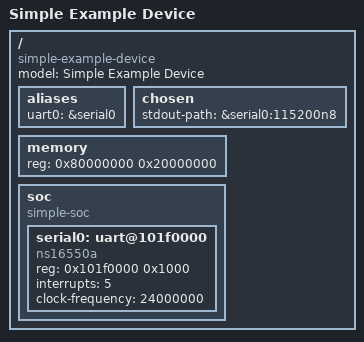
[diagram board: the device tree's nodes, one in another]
/dts-v1/;
/ {
    model = "Simple Example Device";
    compatible = "simple-example-device";

    aliases {
        uart0 = &serial0;
    };

    chosen {
        stdout-path = &serial0:115200n8;
    };

    memory {
        device_type = "memory";
        reg = <0x80000000 0x20000000>; /* 512 MB at 0x80000000 */
    };

    soc {
        #address-cells = <1>;
        #size-cells = <1>;
        compatible = "simple-soc";

        serial0: uart@101f0000 {
            compatible = "ns16550a";
            reg = <0x101f0000 0x1000>;
            interrupts = <5>;
            clock-frequency = <24000000>;
        };
    };
};
